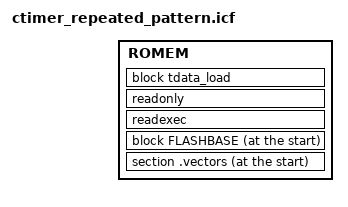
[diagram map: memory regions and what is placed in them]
//*****************************************************************************
//
// ctimer_repeated_pattern.icf
//
// IAR linker Configuration File
//
//*****************************************************************************

//*****************************************************************************
//
// Copyright (c) 2024, Ambiq Micro, Inc.
// All rights reserved.
//
// Redistribution and use in source and binary forms, with or without
// modification, are permitted provided that the following conditions are met:
//
// 1. Redistributions of source code must retain the above copyright notice,
// this list of conditions and the following disclaimer.
//
// 2. Redistributions in binary form must reproduce the above copyright
// notice, this list of conditions and the following disclaimer in the
// documentation and/or other materials provided with the distribution.
//
// 3. Neither the name of the copyright holder nor the names of its
// contributors may be used to endorse or promote products derived from this
// software without specific prior written permission.
//
// Third party software included in this distribution is subject to the
// additional license terms as defined in the /docs/licenses directory.
//
// THIS SOFTWARE IS PROVIDED BY THE COPYRIGHT HOLDERS AND CONTRIBUTORS "AS IS"
// AND ANY EXPRESS OR IMPLIED WARRANTIES, INCLUDING, BUT NOT LIMITED TO, THE
// IMPLIED WARRANTIES OF MERCHANTABILITY AND FITNESS FOR A PARTICULAR PURPOSE
// ARE DISCLAIMED. IN NO EVENT SHALL THE COPYRIGHT HOLDER OR CONTRIBUTORS BE
// LIABLE FOR ANY DIRECT, INDIRECT, INCIDENTAL, SPECIAL, EXEMPLARY, OR
// CONSEQUENTIAL DAMAGES (INCLUDING, BUT NOT LIMITED TO, PROCUREMENT OF
// SUBSTITUTE GOODS OR SERVICES; LOSS OF USE, DATA, OR PROFITS; OR BUSINESS
// INTERRUPTION) HOWEVER CAUSED AND ON ANY THEORY OF LIABILITY, WHETHER IN
// CONTRACT, STRICT LIABILITY, OR TORT (INCLUDING NEGLIGENCE OR OTHERWISE)
// ARISING IN ANY WAY OUT OF THE USE OF THIS SOFTWARE, EVEN IF ADVISED OF THE
// POSSIBILITY OF SUCH DAMAGE.
//
// This is part of revision release_sdk_3_2_0-dd5f40c14b of the AmbiqSuite Development Package.
//
//*****************************************************************************

//
// Define a memory section that covers the entire 4 GB addressable space of the
// processor. (32-bit can address up to 4GB)
//
define memory mem with size = 4G;

//
// Define regions for the various types of internal memory.
//
define region ROMEM    = [from 0x0000C000 size 0x000F4000];
define region RWMEM    = [from 0x10000000 size 0x00060000];

// Thread-local-storage load image
define block tbss                           { section .tbss,      section .tbss.*  };
define block tdata                          { section .tdata,     section .tdata.* };
define block tls with fixed order           { block tbss, block tdata };
define block tdata_load                     { copy of block tdata };

//
// Define blocks for logical groups of data.
//
define block heap  with size = 0, alignment = 0x8, readwrite access { };
define block stack with size = 0x00001000, alignment = 8, readwrite access { };

define block FLASHBASE                  { section .patch };

// Configure Initialization
do not initialize                       { section .non_init, section .non_init.* };
initialize by copy with packing=auto    { section .data, section .data.* };
initialize by symbol __SEGGER_init_heap { block heap };

//
// Place code sections in memory regions.
//
place at start of ROMEM                  { section .vectors, block FLASHBASE };
place in ROMEM                           { readexec, readonly };
place in ROMEM                           { block tdata_load };
place in RWMEM with auto order           { block tls, readwrite, zeroinit };
place in RWMEM with fixed order          { block heap, block stack };


